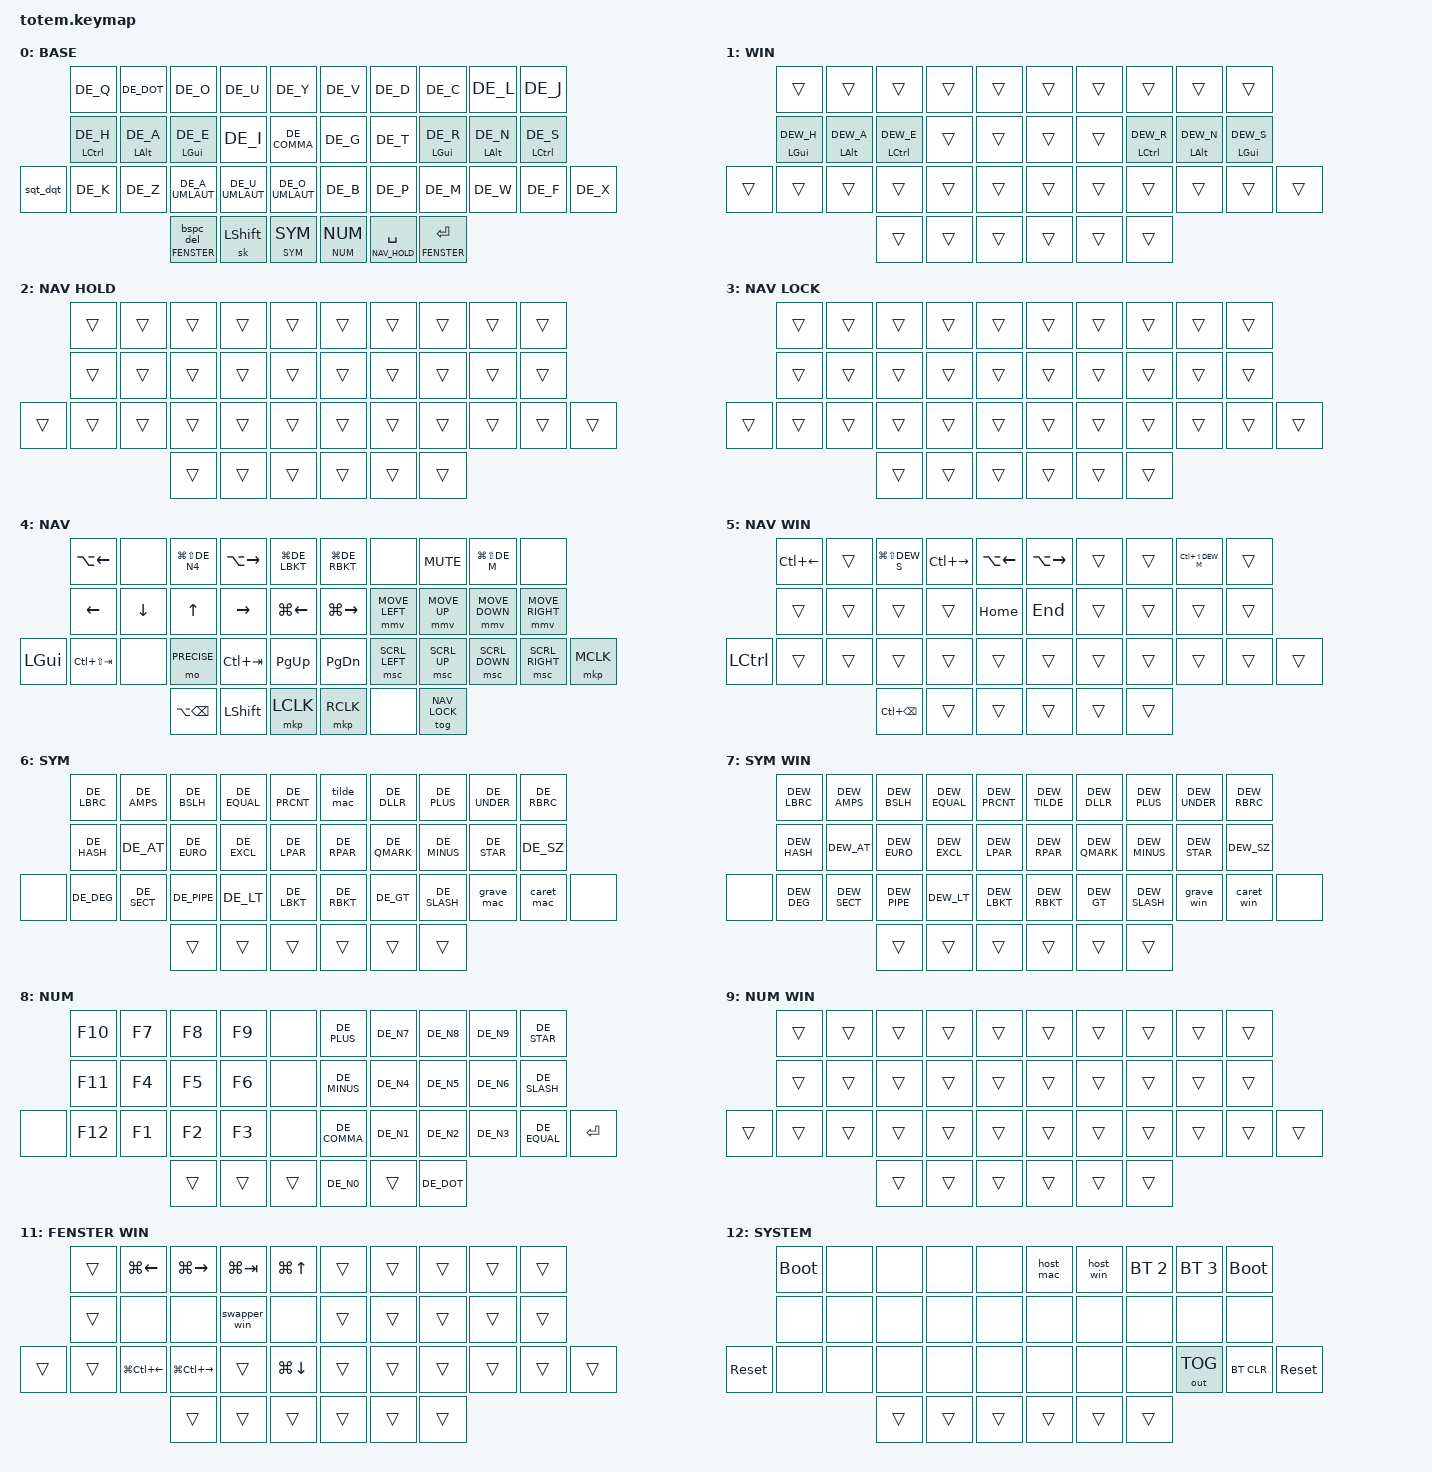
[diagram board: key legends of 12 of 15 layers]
/*
 * TOTEM keymap – anymak:END variant, timeless home-row mods, combos, num-word.
 * Pictures of every layer: readme.md (redrawn automatically after each upload).
 *
 * ── HOW TO EDIT ──────────────────────────────────────────────────────────────────────────
 * 1. Edit THIS file only (config/totem.keymap). On github.com: open it, click the pencil, commit.
 * 2. Each layer's "bindings" list has 38 entries in the order of the position grid below:
 *    top row 0-9, home row 10-19, bottom row 20-31 (20 and 31 = outer keys), thumbs 32-37.
 *    Spaces and line breaks don't matter, only the order.
 * 3. Two systems, one layout. macOS is the default; Windows is an overlay on Bluetooth profile 1.
 *    Every Mac layer has a Windows twin directly below it ("..._win_layer", e.g. sym_layer ->
 *    sym_win_layer). If you change a key in a Mac layer, change the same position in its twin:
 *      - Mac keycodes start with DE_  (keys_de_mac.h), Windows keycodes with DEW_ (keys_de_win.h)
 *      - &trans in a twin means "same as the Mac key" – fine for letters, digits, layer keys
 *      - shortcuts: Cmd on macOS = Ctrl on Windows (LG(...) -> LC(...))
 *    Combos come in pairs too (undo_mac / undo_win ...).
 *    The GitHub build runs tools/check_keymap.py first and stops with a plain message if a Mac
 *    key and its Windows twin don't match. (If a difference is intended, see the table at the
 *    top of tools/check_keymap.py.)
 * 4. Key names: docs/keycodes.md lists every character with its name (e.g. § = DE_SECT / DEW_SECT).
 * 5. After the build (GitHub -> Actions -> firmware.zip): for keymap-only changes flashing the
 *    LEFT half is enough. A typo shows up as a failed build with a line number.
 * ──────────────────────────────────────────────────────────────────────────────────────────
 *
 * Two hosts, ONE physical layout:
 *   macOS (default, Bluetooth profile 0)  – input source "Deutsch", keycodes from keys_de_mac.h (DE_*)
 *   Windows (overlay, Bluetooth profile 1) – layout "Deutsch",      keycodes from keys_de_win.h (DEW_*)
 * Switch hosts with the "Mac" / "Win" keys on SYSTEM (hold Space + Num). After power-off the keyboard starts in macOS mode.
 *
 * Key positions (used by the bindings lists, combos and home-row-mod settings):
 *
 *        0   1   2   3   4       5   6   7   8   9
 *       10  11  12  13  14      15  16  17  18  19
 *   20  21  22  23  24  25      26  27  28  29  30  31
 *               32  33  34      35  36  37
 */

#include <behaviors.dtsi>
#include <dt-bindings/zmk/bt.h>
#include <dt-bindings/zmk/keys.h>
#include <dt-bindings/zmk/outputs.h>
#define ZMK_POINTING_DEFAULT_MOVE_VAL 2400   // mouse keys top speed (ZMK default 600); must come before pointing.h
#include <dt-bindings/zmk/pointing.h>
#include <input/processors.dtsi>          // &zip_xy_scaler for the precision key
#include <behaviors/num_word.dtsi>   // from module urob/zmk-auto-layer (see west.yml)
#include "keys_de_mac.h"             // macOS "Deutsch"   -> DE_*
#include "keys_de_win.h"             // Windows "Deutsch" -> DEW_*

// Layer order matters: a higher number wins. Each *_WIN layer sits directly above its macOS
// counterpart and only overrides the keys that differ on Windows (everything else is &trans).
#define BASE      0
#define WIN       1   // Windows overlay for BASE (home-row mods), on via the Windows host key
#define NAV_HOLD  2   // flag (all &trans): on while Space is held
#define NAV_LOCK  3   // flag (all &trans): toggled by Nav pos 37 ("Nav fixed")
#define NAV       4   // conditional: on while NAV_HOLD or NAV_LOCK is on
#define NAV_WIN   5   // conditional: NAV + WIN
#define SYM       6
#define SYM_WIN   7   // conditional: SYM + WIN
#define NUM       8
#define NUM_WIN   9   // conditional: NUM + WIN (empty: NUM is identical on both systems)
#define FENSTER     10  // window layer: hold Backspace (pos 32) or pos 37
#define FENSTER_WIN 11  // conditional: FENSTER + WIN
#define SYSTEM      12  // conditional: Space (NAV_HOLD) + Num held together
#define SYSTEM_WIN  13  // conditional: SYSTEM + WIN (empty: SYSTEM is identical on both systems)
#define PRECISE     14  // flag (all &trans): held via Nav pos 23, slows the mouse keys to 1/3

// Key groups for the timeless home-row mods (a mod only fires if the NEXT key is on the other hand)
#define KEYS_L 0 1 2 3 4 10 11 12 13 14 20 21 22 23 24 25
#define KEYS_R 5 6 7 8 9 15 16 17 18 19 26 27 28 29 30 31
#define THUMBS 32 33 34 35 36 37

/ {
    behaviors {
        // Timeless home-row mods (urob): left hand
        hml: hml {
            compatible = "zmk,behavior-hold-tap";
            #binding-cells = <2>;
            flavor = "balanced";
            tapping-term-ms = <280>;
            quick-tap-ms = <175>;
            require-prior-idle-ms = <150>;
            bindings = <&kp>, <&kp>;
            hold-trigger-key-positions = <KEYS_R THUMBS>;
            hold-trigger-on-release;
        };

        // Timeless home-row mods (urob): right hand
        hmr: hmr {
            compatible = "zmk,behavior-hold-tap";
            #binding-cells = <2>;
            flavor = "balanced";
            tapping-term-ms = <280>;
            quick-tap-ms = <175>;
            require-prior-idle-ms = <150>;
            bindings = <&kp>, <&kp>;
            hold-trigger-key-positions = <KEYS_L THUMBS>;
            hold-trigger-on-release;
        };

        // Space: tap = space, hold = navigation layer. quick-tap lets you hold space to repeat.
        lt_spc: lt_spc {
            compatible = "zmk,behavior-hold-tap";
            #binding-cells = <2>;
            flavor = "balanced";
            tapping-term-ms = <200>;
            quick-tap-ms = <175>;
            bindings = <&mo>, <&kp>;
        };

        // Symbol key: tap = one-shot symbol layer (next key only), hold = symbol layer.
        // balanced: holding Sym and typing a symbol decides "hold" as soon as that key is released,
        // no 200 ms wait. No misfire risk: tap and hold both put the next key on SYM.
        sym_key: sym_key {
            compatible = "zmk,behavior-hold-tap";
            #binding-cells = <2>;
            flavor = "balanced";
            tapping-term-ms = <200>;
            bindings = <&mo>, <&sl>;
        };

        // Sys key (right thumb, tucked): tap = Enter, hold = system layer.
        // hold-preferred: held longer than 200 ms without another key = nothing (no accidental Enter).
        lt_ret: lt_ret {
            compatible = "zmk,behavior-hold-tap";
            #binding-cells = <2>;
            flavor = "hold-preferred";
            tapping-term-ms = <200>;
            bindings = <&mo>, <&kp>;
        };

        // Number key: tap = num-word (numbers until a non-number key), hold = number layer
        num_key: num_key {
            compatible = "zmk,behavior-hold-tap";
            #binding-cells = <2>;
            flavor = "tap-preferred";
            tapping-term-ms = <200>;
            bindings = <&mo>, <&num_word>;
        };

        // Backspace key (left thumb, outer): tap = bspc_del (below), hold = window layer (FENSTER),
        // tap then hold = Backspace auto-repeats (quick-tap). tap-preferred: a fast Backspace while
        // typing never opens the layer; hold about 0.2 s first. Delete word is on Nav pos 32.
        bsf: bsf {
            compatible = "zmk,behavior-hold-tap";
            #binding-cells = <2>;
            flavor = "tap-preferred";
            tapping-term-ms = <200>;
            quick-tap-ms = <200>;
            bindings = <&mo>, <&bspc_del>;
        };

        // Swapper (Callum/urob, tri-state module): first tap holds Cmd (Windows: Alt) and taps Tab,
        // further taps send Tab. On the window layer: pos 13 = forward, pos 10 (Shift+Tab) = back;
        // 10 and Shift (33) keep it open; releasing the window layer key or any other key releases
        // Cmd/Alt and selects the app.
        swapper_mac: swapper_mac {
            compatible = "zmk,behavior-tri-state";
            #binding-cells = <0>;
            bindings = <&kt LGUI>, <&kp TAB>, <&kt LGUI>;
            ignored-key-positions = <10 33>;
        };
        swapper_win: swapper_win {
            compatible = "zmk,behavior-tri-state";
            #binding-cells = <0>;
            bindings = <&kt LALT>, <&kp TAB>, <&kt LALT>;
            ignored-key-positions = <10 33>;
        };

        // Backspace: plain = Backspace, with Shift (incl. one-shot Shift) = forward Delete.
        // Shift is not sent along (keep-mods empty). Same keycodes on macOS and Windows.
        bspc_del: bspc_del {
            compatible = "zmk,behavior-mod-morph";
            #binding-cells = <0>;
            bindings = <&kp BSPC>, <&kp DEL>;
            mods = <(MOD_LSFT|MOD_RSFT)>;
        };

        // Apostrophe: plain = ' , with Shift = "  (same keycodes on macOS and Windows)
        sqt_dqt: sqt_dqt {
            compatible = "zmk,behavior-mod-morph";
            #binding-cells = <0>;
            bindings = <&kp DE_SQT>, <&kp DE_DQT>;
            mods = <(MOD_LSFT|MOD_RSFT)>;
        };
    };
};

&num_word {
    // keys that keep num-word alive (identical keycodes on macOS and Windows)
    continue-list = <BSPC DEL DE_COMMA DE_DOT DE_MINUS DE_PLUS DE_STAR DE_SLASH DE_EQUAL>;
    ignore-modifiers;   // Shift does not end num-word: Shift+. = :  Shift+, = ;  (the dot/comma stay in the list)
};

/ {
    conditional_layers {
        compatible = "zmk,conditional-layers";
        // NAV is on while Space is held (NAV_HOLD) OR Nav is fixed (NAV_LOCK, toggled by Nav pos 37).
        // NAV must only be switched through these two flags: ZMK turns a conditional layer off
        // whenever none of its conditions is met.
        nav_hold {
            if-layers = <NAV_HOLD>;
            then-layer = <NAV>;
        };
        nav_lock {
            if-layers = <NAV_LOCK>;
            then-layer = <NAV>;
        };
        // Windows variants: active only while the Windows overlay is on
        nav_win {
            if-layers = <NAV WIN>;
            then-layer = <NAV_WIN>;
        };
        sym_win {
            if-layers = <SYM WIN>;
            then-layer = <SYM_WIN>;
        };
        num_win {
            if-layers = <NUM WIN>;
            then-layer = <NUM_WIN>;
        };
        fenster_win {
            if-layers = <FENSTER WIN>;
            then-layer = <FENSTER_WIN>;
        };
        // SYSTEM: Space and Num held together (right thumb). Rarely used, so a deliberate two-key grip.
        system {
            if-layers = <NAV_HOLD NUM>;
            then-layer = <SYSTEM>;
        };
        system_win {
            if-layers = <SYSTEM WIN>;
            then-layer = <SYSTEM_WIN>;
        };
    };

    combos {
        compatible = "zmk,combos";

        // Combos work on the base layer (BASE, and WIN when the Windows overlay is on).
        // Esc and Tab also on NUM: there these positions are F-keys, not digits, and Tab/Esc are
        // needed while num-word is on (e.g. moving between table cells). On the other layers the
        // combo positions are digits, app/tab keys etc. and must not trigger.
        // require-prior-idle-ms: combos do not fire while you are typing fast.
        // Esc, Tab, Enter and media are identical on both systems.
        combo_esc {
            timeout-ms = <30>;
            require-prior-idle-ms = <150>;
            key-positions = <0 1>;          // top-left: q + .
            layers = <BASE WIN NUM NUM_WIN>;
            bindings = <&kp ESC>;
        };
        combo_tab {
            timeout-ms = <30>;
            require-prior-idle-ms = <150>;
            key-positions = <1 2>;          // . + o
            layers = <BASE WIN NUM NUM_WIN>;
            bindings = <&kp TAB>;
        };

        // Enter: t + r + n (right home row) together. 3-key combo, blocked for 100 ms after the
        // last key press so it cannot fire inside words ("Kontrolle", "control").
        combo_enter {
            timeout-ms = <40>;
            require-prior-idle-ms = <100>;
            key-positions = <16 17 18>;
            layers = <BASE WIN>;
            bindings = <&kp RET>;
        };

        // Media: v+d previous track, l+j next track, '+k quieter (left outer), f+x louder (right outer).
        combo_prev  { timeout-ms = <30>; require-prior-idle-ms = <150>; key-positions = <5 6>;   layers = <BASE WIN>; bindings = <&kp C_PREV>; };
        combo_next  { timeout-ms = <30>; require-prior-idle-ms = <150>; key-positions = <8 9>;   layers = <BASE WIN>; bindings = <&kp C_NEXT>; };
        combo_voldn { timeout-ms = <30>; require-prior-idle-ms = <150>; key-positions = <20 21>; layers = <BASE WIN>; bindings = <&kp C_VOL_DN>; };
        combo_volup { timeout-ms = <30>; require-prior-idle-ms = <150>; key-positions = <30 31>; layers = <BASE WIN>; bindings = <&kp C_VOL_UP>; };

        // Clipboard on the left bottom row in QWERTZ order (k+z Undo, z+ä Cut, ä+ü Copy, ü+ö Paste),
        // Redo mirrored on the right bottom row (w+f). macOS: Cmd+key, Windows: Ctrl+key.
        undo_mac  { timeout-ms = <30>; require-prior-idle-ms = <150>; key-positions = <21 22>; layers = <BASE>; bindings = <&kp LG(DE_Z)>; };
        cut_mac   { timeout-ms = <30>; require-prior-idle-ms = <150>; key-positions = <22 23>; layers = <BASE>; bindings = <&kp LG(DE_X)>; };
        copy_mac  { timeout-ms = <30>; require-prior-idle-ms = <150>; key-positions = <23 24>; layers = <BASE>; bindings = <&kp LG(DE_C)>; };
        paste_mac { timeout-ms = <30>; require-prior-idle-ms = <150>; key-positions = <24 25>; layers = <BASE>; bindings = <&kp LG(DE_V)>; };
        redo_mac  { timeout-ms = <30>; require-prior-idle-ms = <150>; key-positions = <29 30>; layers = <BASE>; bindings = <&kp LG(LS(DE_Z))>; };

        undo_win  { timeout-ms = <30>; require-prior-idle-ms = <150>; key-positions = <21 22>; layers = <WIN>; bindings = <&kp LC(DEW_Z)>; };
        cut_win   { timeout-ms = <30>; require-prior-idle-ms = <150>; key-positions = <22 23>; layers = <WIN>; bindings = <&kp LC(DEW_X)>; };
        copy_win  { timeout-ms = <30>; require-prior-idle-ms = <150>; key-positions = <23 24>; layers = <WIN>; bindings = <&kp LC(DEW_C)>; };
        paste_win { timeout-ms = <30>; require-prior-idle-ms = <150>; key-positions = <24 25>; layers = <WIN>; bindings = <&kp LC(DEW_V)>; };
        redo_win  { timeout-ms = <30>; require-prior-idle-ms = <150>; key-positions = <29 30>; layers = <WIN>; bindings = <&kp LC(DEW_Y)>; };
    };

    macros {
        // Host keys: select the Bluetooth profile AND the matching overlay in one press.
        // &to keeps only the default layer (BASE) plus the named one, so pressing twice is harmless.
        host_mac: host_mac {
            compatible = "zmk,behavior-macro";
            #binding-cells = <0>;
            bindings = <&bt BT_SEL 0 &to BASE>;
        };
        host_win: host_win {
            compatible = "zmk,behavior-macro";
            #binding-cells = <0>;
            bindings = <&bt BT_SEL 1 &to WIN>;
        };

        // Window commands (FENSTER layer, macOS): Globe(Fn)+Ctrl+<key> sent in one go.
        // &fnctl DE_F = fill, &fnctl DE_C = center, &fnctl DE_R = previous size. Halves and "two windows"
        // can NOT use Fn+Ctrl+arrow: macOS drops Fn on arrows from non-Apple sources (Apple forum thread
        // 766200, FB15532267). They send Ctrl+Opt+Cmd(+Shift)+arrow instead, assigned in macOS:
        // App Shortcuts > All Applications > Window > Move & Resize > Left / Right / Left & Right / Right & Left.
        // REQUIRES on the Mac: System Settings > Keyboard > Keyboard Shortcuts > Modifier Keys,
        // select the TOTEM, set "Caps Lock" to "Globe". Without it these keys toggle Caps Lock.
        // A macro is needed: Caps Lock is no modifier.
        fnctl: fnctl {
            compatible = "zmk,behavior-macro-one-param";
            #binding-cells = <1>;
            bindings = <&macro_press &kp CAPS &kp LCTRL>, <&macro_param_1to1>, <&macro_tap &kp MACRO_PLACEHOLDER>, <&macro_release &kp LCTRL &kp CAPS>;
        };

        // macOS: Option+N is a dead key; add Space so ~ appears immediately (Windows types ~ directly)
        tilde_mac: tilde_mac {
            compatible = "zmk,behavior-macro";
            #binding-cells = <0>;
            bindings = <&macro_tap &kp DE_TILDE &kp SPACE>;
        };

        // ^ is a dead key on both systems; add Space so ^ appears immediately.
        // Separate Mac/Windows versions: the ^ key is sent differently on macOS (see keys_de_mac.h).
        caret_mac: caret_mac {
            compatible = "zmk,behavior-macro";
            #binding-cells = <0>;
            bindings = <&macro_tap &kp DE_CARET &kp SPACE>;
        };
        caret_win: caret_win {
            compatible = "zmk,behavior-macro";
            #binding-cells = <0>;
            bindings = <&macro_tap &kp DEW_CARET &kp SPACE>;
        };

        // ` (backtick) is a dead key on both systems (Shift + the key right of ß); add Space.
        grave_mac: grave_mac {
            compatible = "zmk,behavior-macro";
            #binding-cells = <0>;
            bindings = <&macro_tap &kp DE_GRAVE &kp SPACE>;
        };
        grave_win: grave_win {
            compatible = "zmk,behavior-macro";
            #binding-cells = <0>;
            bindings = <&macro_tap &kp DEW_GRAVE &kp SPACE>;
        };
    };

    keymap {
        compatible = "zmk,keymap";

        // BASE – letters. Home-row mods by function, same finger on both systems:
        //   pinky = Ctrl (macOS) / Win (Windows), ring = Option / Alt, middle = Cmd / Ctrl.
        //   Thumbs: left Backspace | Shift | Sym, right Num | Space/Nav | Enter/Sys. Shift and Space on the middle keys.
        //   Backspace: tap = Backspace (with Shift: Delete), hold = delete word, tap+hold = repeat.
        //   Combos (see "combos" above, base layer only): Enter = t+r+n, Esc/Tab, clipboard, media.
        base_layer {
            display-name = "BASE";
            bindings = <
            &kp DE_Q        &kp DE_DOT       &kp DE_O          &kp DE_U        &kp DE_Y         &kp DE_V        &kp DE_D        &kp DE_C          &kp DE_L          &kp DE_J
            &hml LCTRL DE_H &hml LALT DE_A   &hml LGUI DE_E    &kp DE_I        &kp DE_COMMA     &kp DE_G        &kp DE_T        &hmr LGUI DE_R    &hmr LALT DE_N    &hmr LCTRL DE_S
&sqt_dqt         &kp DE_K       &kp DE_Z         &kp DE_A_UMLAUT   &kp DE_U_UMLAUT &kp DE_O_UMLAUT  &kp DE_B        &kp DE_P        &kp DE_M          &kp DE_W          &kp DE_F          &kp DE_X
                                                 &bsf FENSTER 0    &sk LSHFT             &sym_key SYM SYM               &num_key NUM NUM   &lt_spc NAV_HOLD SPACE   &lt_ret FENSTER RET
            >;
        };

        // WIN – Windows overlay: only the home-row mods differ (pinky Win, ring Alt, middle Ctrl).
        win_layer {
            display-name = "WIN";
            bindings = <
            &trans          &trans           &trans            &trans          &trans           &trans          &trans          &trans            &trans            &trans
            &hml LGUI DEW_H &hml LALT DEW_A  &hml LCTRL DEW_E  &trans          &trans           &trans          &trans          &hmr LCTRL DEW_R  &hmr LALT DEW_N   &hmr LGUI DEW_S
&trans           &trans         &trans           &trans            &trans          &trans           &trans          &trans          &trans            &trans            &trans            &trans
                                                 &trans            &trans             &trans             &trans            &trans     &trans
            >;
        };

        // NAV HOLD / NAV LOCK – flag layers, never seen (all &trans). Either one switches NAV on.
        nav_hold_layer {
            display-name = "NAV HOLD";
            bindings = <
            &trans  &trans  &trans  &trans  &trans    &trans  &trans  &trans  &trans  &trans
            &trans  &trans  &trans  &trans  &trans    &trans  &trans  &trans  &trans  &trans
&trans      &trans  &trans  &trans  &trans  &trans    &trans  &trans  &trans  &trans  &trans  &trans
                            &trans  &trans  &trans    &trans  &trans  &trans
            >;
        };
        nav_lock_layer {
            display-name = "NAV LOCK";
            bindings = <
            &trans  &trans  &trans  &trans  &trans    &trans  &trans  &trans  &trans  &trans
            &trans  &trans  &trans  &trans  &trans    &trans  &trans  &trans  &trans  &trans
&trans      &trans  &trans  &trans  &trans  &trans    &trans  &trans  &trans  &trans  &trans  &trans
                            &trans  &trans  &trans    &trans  &trans  &trans
            >;
        };

        // NAV – hold Space (right thumb, middle key), or press Nav pos 37 to keep it on (again = off).
        //   Left: arrows on the home row (10 ←, 11 ↓, 12 ↑, 13 →), word left/right (0/3), screenshot (2),
        //         Cmd (20), browser tabs (21/24), app back (22) / app swapper (23), PgUp (25).
        //   Middle: browser back/forward (4/5), Home/End (14/15), PgDn (26).
        //   Right: mute (7), Teams microphone (8), mouse pointer on the home row (16-19),
        //          scrolling below (27-30), middle click (31).
        //   Precision key (23, hold: mouse keys at 1/4 speed).
        //   Thumbs: delete word (32), Shift (33, as on base), clicks left/right (34/35), Nav fixed (37).
        //   macOS keystrokes here; the Windows equivalents are in nav_win_layer.
        nav_layer {
            display-name = "NAV";
            bindings = <
            &kp LA(LEFT)   &none            &kp LG(LS(DE_N4))  &kp LA(RIGHT)  &kp LG(DE_LBKT)  &kp LG(DE_RBKT)  &none            &kp C_MUTE       &kp LG(LS(DE_M))  &none
            &kp LEFT       &kp DOWN         &kp UP             &kp RIGHT      &kp LG(LEFT)     &kp LG(RIGHT)    &mmv MOVE_LEFT   &mmv MOVE_UP     &mmv MOVE_DOWN    &mmv MOVE_RIGHT
&kp LGUI   &kp LC(LS(TAB))  &none            &mo PRECISE        &kp LC(TAB)    &kp PG_UP        &kp PG_DN        &msc SCRL_LEFT   &msc SCRL_UP     &msc SCRL_DOWN    &msc SCRL_RIGHT  &mkp MCLK
                                              &kp LA(BSPC)       &kp LSHFT      &mkp LCLK        &mkp RCLK        &none            &tog NAV_LOCK
            >;
        };

        nav_win_layer {
            display-name = "NAV WIN";
            bindings = <
            &kp LC(LEFT)   &trans           &kp LG(LS(DEW_S))  &kp LC(RIGHT)  &kp LA(LEFT)     &kp LA(RIGHT)    &trans           &trans           &kp LC(LS(DEW_M)) &trans
            &trans         &trans           &trans             &trans         &kp HOME         &kp END          &trans           &trans           &trans            &trans
&kp LCTRL  &trans           &trans           &trans             &trans         &trans           &trans           &trans           &trans           &trans            &trans           &trans
                                              &kp LC(BSPC)       &trans         &trans           &trans           &trans           &trans
            >;
        };

        // SYM – tap the Sym key for ONE symbol, hold it for several. ~ ^ ` are typed directly.
        //   Sorted by how often they are used: ! @ ? * on the home row, { } [ ] | ~ ^ ` outside.
        //   ' " : ; are not here: they are Shift on the base layer (' → ", , → ;, . → :).
        sym_layer {
            display-name = "SYM";
            bindings = <
            &kp DE_LBRC   &kp DE_AMPS   &kp DE_BSLH   &kp DE_EQUAL  &kp DE_PRCNT    &tilde_mac    &kp DE_DLLR   &kp DE_PLUS   &kp DE_UNDER  &kp DE_RBRC
            &kp DE_HASH   &kp DE_AT     &kp DE_EURO   &kp DE_EXCL   &kp DE_LPAR     &kp DE_RPAR   &kp DE_QMARK  &kp DE_MINUS  &kp DE_STAR   &kp DE_SZ
&none       &kp DE_DEG    &kp DE_SECT   &kp DE_PIPE   &kp DE_LT     &kp DE_LBKT     &kp DE_RBKT   &kp DE_GT     &kp DE_SLASH  &grave_mac    &caret_mac    &none
                                        &trans        &trans        &trans          &trans        &trans        &trans
            >;
        };

        sym_win_layer {
            display-name = "SYM WIN";
            bindings = <
            &kp DEW_LBRC   &kp DEW_AMPS   &kp DEW_BSLH   &kp DEW_EQUAL  &kp DEW_PRCNT    &kp DEW_TILDE  &kp DEW_DLLR   &kp DEW_PLUS   &kp DEW_UNDER  &kp DEW_RBRC
            &kp DEW_HASH   &kp DEW_AT     &kp DEW_EURO   &kp DEW_EXCL   &kp DEW_LPAR     &kp DEW_RPAR   &kp DEW_QMARK  &kp DEW_MINUS  &kp DEW_STAR   &kp DEW_SZ
&none       &kp DEW_DEG    &kp DEW_SECT   &kp DEW_PIPE   &kp DEW_LT     &kp DEW_LBKT     &kp DEW_RBKT   &kp DEW_GT     &kp DEW_SLASH  &grave_win     &caret_win    &none
                                        &trans        &trans        &trans          &trans        &trans        &trans
            >;
        };

        // NUM – tap the Num key for num-word, hold it for the layer. Numpad on the RIGHT hand like on a
        //   full-size keyboard (0 on the right thumb where the Num key is, . on the tucked thumb),
        //   F-keys in the same pattern on the left (F7-F9 top, F4-F6 home, F1-F3 bottom, F10-F12 outer).
        //   Left thumbs stay as on the base layer (Backspace, Shift, Sym): Shift+. = :  Shift+, = ;
        //   Num-word ends with Space or any letter. Identical keycodes on macOS and Windows.
        num_layer {
            display-name = "NUM";
            bindings = <
            &kp F10   &kp F7   &kp F8   &kp F9   &none      &kp DE_PLUS    &kp DE_N7  &kp DE_N8  &kp DE_N9  &kp DE_STAR
            &kp F11   &kp F4   &kp F5   &kp F6   &none      &kp DE_MINUS   &kp DE_N4  &kp DE_N5  &kp DE_N6  &kp DE_SLASH
&none       &kp F12   &kp F1   &kp F2   &kp F3   &none      &kp DE_COMMA   &kp DE_N1  &kp DE_N2  &kp DE_N3  &kp DE_EQUAL   &kp RET
                               &trans   &trans   &trans     &kp DE_N0      &trans     &kp DE_DOT
            >;
        };

        // NUM WIN – empty; exists so the Windows combos stay active while NUM is held
        num_win_layer {
            display-name = "NUM WIN";
            bindings = <
            &trans  &trans  &trans  &trans  &trans    &trans  &trans  &trans  &trans  &trans
            &trans  &trans  &trans  &trans  &trans    &trans  &trans  &trans  &trans  &trans
&trans      &trans  &trans  &trans  &trans  &trans    &trans  &trans  &trans  &trans  &trans  &trans
                            &trans  &trans  &trans    &trans  &trans  &trans
            >;
        };

        // FENSTER – window layer. Hold Backspace (pos 32, left thumb, about 0.2 s) so the right hand can
        //   stay on the trackball, or hold pos 37 (right thumb; tap = Enter). Left hand only:
        //   top: half left/right (1/2), overview (3), fill (4)
        //   home: app back (10) / app forward (13, swapper), two windows side by side (11/12), center (14)
        //   bottom: desktop left/right (22/23), previous size (25)
        //   macOS: Globe+Ctrl shortcuts via &fnctl (needs Caps Lock -> Globe in macOS settings).
        //   Windows: Win+arrows, Win+Tab, Win+Ctrl+arrows; "two windows" and "center" do not exist there.
        fenster_layer {
            display-name = "FENSTER";
            bindings = <
            &none            &kp LC(LA(LG(LEFT))) &kp LC(LA(LG(RIGHT)))        &kp LC(UP)    &fnctl DE_F       &none  &none  &none  &none  &none
            &kp LS(TAB)      &kp LC(LA(LG(LS(LEFT)))) &kp LC(LA(LG(LS(RIGHT))))    &swapper_mac  &fnctl DE_C       &none  &none  &none  &none  &none
&none       &none            &kp LC(LEFT)       &kp LC(RIGHT)       &none         &fnctl DE_R       &none  &none  &none  &none  &none  &none
                                                &trans              &trans        &trans            &trans &trans &trans
            >;
        };

        fenster_win_layer {
            display-name = "FENSTER WIN";
            bindings = <
            &trans           &kp LG(LEFT)       &kp LG(RIGHT)       &kp LG(TAB)   &kp LG(UP)        &trans &trans &trans &trans &trans
            &trans           &none              &none               &swapper_win  &none             &trans &trans &trans &trans &trans
&trans      &trans           &kp LG(LC(LEFT))   &kp LG(LC(RIGHT))   &trans        &kp LG(DOWN)      &trans &trans &trans &trans &trans &trans
                                                &trans              &trans        &trans            &trans &trans &trans
            >;
        };

        // SYSTEM – hold Space and Num together (right thumb, pos 36 + 35, about 0.2 s). Rarely used:
        //   host keys Mac/Win, Bluetooth, USB/BT, BT clear. Boot (bootloader) and Reset work on the half
        //   where they are pressed: left 0/20, right 9/31.
        system_layer {
            display-name = "SYSTEM";
            bindings = <
            &bootloader  &none  &none  &none  &none    &host_mac  &host_win  &bt BT_SEL 2  &bt BT_SEL 3  &bootloader
            &none        &none  &none  &none  &none    &none      &none      &none         &none         &none
&sys_reset  &none        &none  &none  &none  &none    &none      &none      &none         &out OUT_TOG  &bt BT_CLR    &sys_reset
                                &trans &trans &trans   &trans     &trans     &trans
            >;
        };

        // SYSTEM WIN – empty; SYSTEM is identical on both systems
        system_win_layer {
            display-name = "SYSTEM WIN";
            bindings = <
            &trans  &trans  &trans  &trans  &trans    &trans  &trans  &trans  &trans  &trans
            &trans  &trans  &trans  &trans  &trans    &trans  &trans  &trans  &trans  &trans
&trans      &trans  &trans  &trans  &trans  &trans    &trans  &trans  &trans  &trans  &trans  &trans
                            &trans  &trans  &trans    &trans  &trans  &trans
            >;
        };

        // PRECISE – flag layer (all &trans), held via Nav pos 23. While it is on, the mouse keys move at
        // 1/4 speed (see &mmv_input_listener below).
        precise_layer {
            display-name = "PRECISE";
            bindings = <
            &trans  &trans  &trans  &trans  &trans    &trans  &trans  &trans  &trans  &trans
            &trans  &trans  &trans  &trans  &trans    &trans  &trans  &trans  &trans  &trans
&trans      &trans  &trans  &trans  &trans  &trans    &trans  &trans  &trans  &trans  &trans  &trans
                            &trans  &trans  &trans    &trans  &trans  &trans
            >;
        };
    };
};

// Mouse keys: faster top speed (ZMK_POINTING_DEFAULT_MOVE_VAL above), linear acceleration,
// full speed after 0.3 s (tested 02.11.2026: 1500 / 0.5 s / quadratic was too slow).
&mmv {
    time-to-max-speed-ms = <300>;
    acceleration-exponent = <1>;
};

// Precision key: while PRECISE is on, mouse-key movement is scaled to 1/3.
&mmv_input_listener {
    precise {
        layers = <PRECISE>;
        input-processors = <&zip_xy_scaler 1 3>;
    };
};
